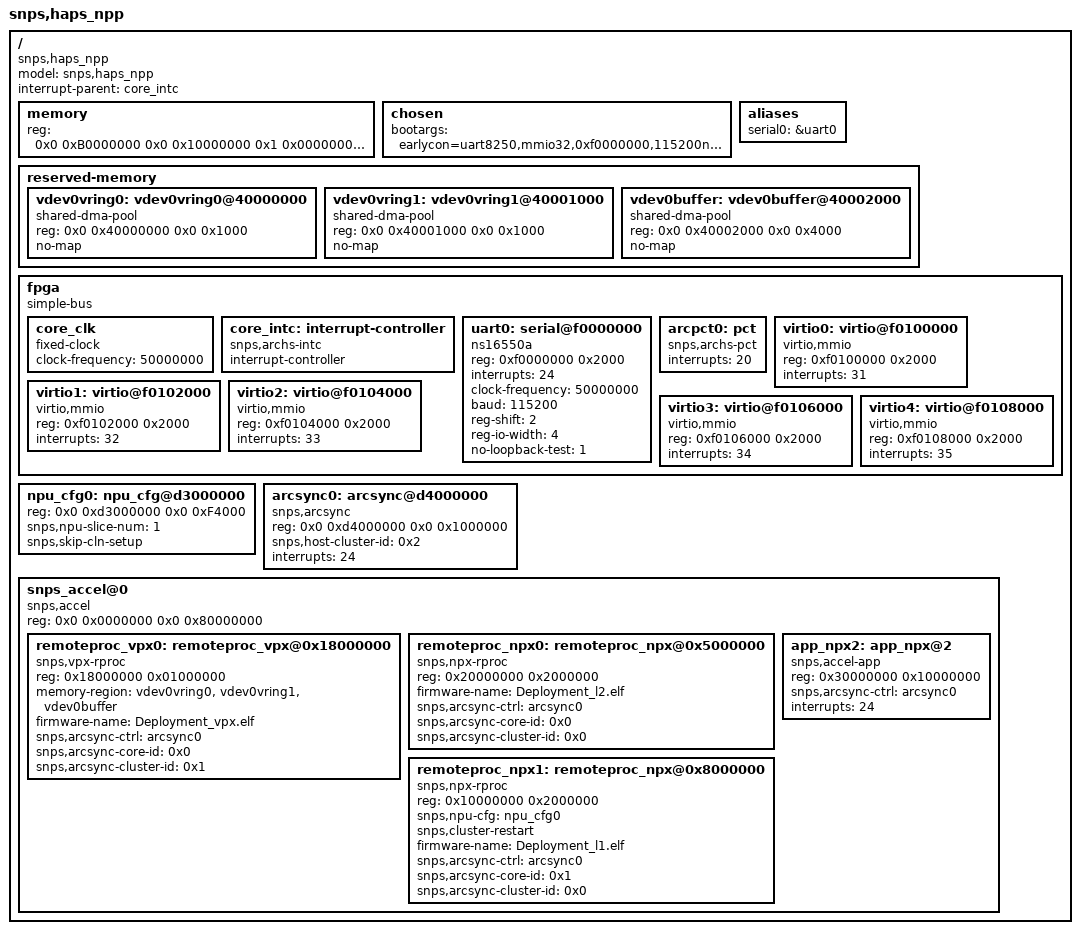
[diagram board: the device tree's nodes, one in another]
// SPDX-License-Identifier: GPL-2.0-only
/*
 * Copyright (C) 2016-2014 Synopsys, Inc. (www.synopsys.com)
 */
/dts-v1/;

/include/ "skeleton_hs.dtsi"

/ {
	model = "snps,haps_npp";
	compatible = "snps,haps_npp";
	#address-cells = <2>;
	#size-cells = <2>;
	interrupt-parent = <&core_intc>;

	memory {
		device_type = "memory";
		/* CONFIG_LINUX_RAM_BASE needs to match low mem start */
		reg = <0x0 0xB0000000 0x0 0x10000000	/* 1 GB low mem */
		       0x1 0x00000000 0x0 0x40000000>;	/* 1 GB highmem */
	};

	chosen {
		bootargs = "earlycon=uart8250,mmio32,0xf0000000,115200n8 console=ttyS0,115200n8 debug print-fatal-signals=1 drm.debug=0";
	};

	aliases {
		serial0 = &uart0;
	};

	reserved-memory {
		#address-cells = <2>;
		#size-cells = <2>;
		ranges;

		vdev0vring0: vdev0vring0@40000000 {
			compatible = "shared-dma-pool";
			reg = <0x0 0x40000000 0x0 0x1000>;
			no-map;
		};

		vdev0vring1: vdev0vring1@40001000 {
			compatible = "shared-dma-pool";
			reg = <0x0 0x40001000 0x0 0x1000>;
			no-map;
		};

		vdev0buffer: vdev0buffer@40002000 {
			compatible = "shared-dma-pool";
			reg = <0x0 0x40002000 0x0 0x4000>;
			no-map;
		};
	};

	fpga {
		compatible = "simple-bus";
		#address-cells = <1>;
		#size-cells = <1>;

		/* only perip space at end of low mem accessible
			  bus addr,  parent bus addr, size    */
		ranges = <0x80000000 0x0 0x80000000 0x80000000>;

		core_clk: core_clk {
			#clock-cells = <0>;
			compatible = "fixed-clock";
			clock-frequency = <50000000>;
		};

		core_intc: interrupt-controller {
			compatible = "snps,archs-intc";
			interrupt-controller;
			#interrupt-cells = <1>;
		};

		uart0: serial@f0000000 {
			compatible = "ns16550a";
			reg = <0xf0000000 0x2000>;
			interrupts = <24>;
			clock-frequency = <50000000>;
			baud = <115200>;
			reg-shift = <2>;
			reg-io-width = <4>;
			no-loopback-test = <1>;
		};

		arcpct0: pct {
			compatible = "snps,archs-pct";
			#interrupt-cells = <1>;
			interrupts = <20>;
		};

		virtio0: virtio@f0100000 {
			compatible = "virtio,mmio";
			reg = <0xf0100000 0x2000>;
			interrupts = <31>;
		};

		virtio1: virtio@f0102000 {
			compatible = "virtio,mmio";
			reg = <0xf0102000 0x2000>;
			interrupts = <32>;
		};

		virtio2: virtio@f0104000 {
			compatible = "virtio,mmio";
			reg = <0xf0104000 0x2000>;
			interrupts = <33>;
		};

		virtio3: virtio@f0106000 {
			compatible = "virtio,mmio";
			reg = <0xf0106000 0x2000>;
			interrupts = <34>;
		};

		virtio4: virtio@f0108000 {
			compatible = "virtio,mmio";
			reg = <0xf0108000 0x2000>;
			interrupts = <35>;
		};
	};

	npu_cfg0: npu_cfg@d3000000 {
		reg = <0x0 0xd3000000 0x0 0xF4000>;
		snps,npu-slice-num = <1>;
		snps,skip-cln-setup;
	};

	arcsync0: arcsync@d4000000 {
		compatible = "snps,arcsync";
		reg = <0x0 0xd4000000 0x0 0x1000000>;
		snps,host-cluster-id = <0x2>;
		interrupts = <24>;
	};

	snps_accel@0 {
		compatible = "snps,accel", "simple-bus";
		#address-cells = <1>;
		#size-cells = <1>;
		reg = <0x0 0x0000000 0x0 0x80000000>;
		ranges = <0x0 0x0 0x0 0x80000000>;

		remoteproc_vpx0: remoteproc_vpx@0x18000000 {
			compatible = "snps,vpx-rproc";
			reg = <0x18000000 0x01000000>;
			memory-region = <&vdev0vring0>, <&vdev0vring1>, <&vdev0buffer>;
			firmware-name = "Deployment_vpx.elf";
			snps,arcsync-ctrl = <&arcsync0>;
			snps,arcsync-core-id = <0x0>;
			snps,arcsync-cluster-id = <0x1>;
		};

		remoteproc_npx0: remoteproc_npx@0x5000000 {
			compatible = "snps,npx-rproc";
			reg = <0x20000000 0x2000000>;
			firmware-name = "Deployment_l2.elf";
			snps,arcsync-ctrl = <&arcsync0>;
			snps,arcsync-core-id = <0x0>;
			snps,arcsync-cluster-id = <0x0>;
		};

		remoteproc_npx1: remoteproc_npx@0x8000000 {
			compatible = "snps,npx-rproc";
			reg = <0x10000000 0x2000000>;
			snps,npu-cfg = <&npu_cfg0>;
			snps,cluster-restart;
			firmware-name = "Deployment_l1.elf";
			snps,arcsync-ctrl = <&arcsync0>;
			snps,arcsync-core-id = <0x1>;
			snps,arcsync-cluster-id = <0x0>;
		};

		app_npx2: app_npx@2 {
			compatible = "snps,accel-app";
			reg = <0x30000000 0x10000000>;
			snps,arcsync-ctrl = <&arcsync0>;
			interrupts = <24>;
		};
	};
};
